# Cortex_M1 register map
Vendor: Arm Ltd.; Series: ARMv6-M; File version: 1.0.0
Cortex-M1 core peripherals (ARMv6-M): System Control Space and CoreSight debug components. Generated from CMSIS-Core 6.3.0 (CMSIS-Core 6.1) core_cm1.h with descriptions from the ARMv6-M Architecture Reference Manual and the Cortex-M1 Technical Reference Manual.
CPU: CM1 r0p0, little endian, no MPU, no FPU, 2 interrupt priority bits
Registers are 32-bit, read-only, reset 0x0 unless marked. A register's access mark holds for its fields unless they carry their own. Offsets are from the block's base; lines under a group give offsets from that group; [hi:lo] are bit positions; {n}, {i} and the like mark numbered series; 'fields as' and 'values as' point back to an identical list; <NAME> marks a mode.

## Memory map
0xE0001000 DWT blocks up to offset 0x1000 — Data Watchpoint and Trace unit: cycle counter and profiling counters, PC sampling, exception trace, and address/data comparators that raise watchpoints (halt or DebugMonitor), trigger the ETM/CTI or emit data trace. Needs DEMCR.TRCENA = 1.
0xE0002000 BPU blocks up to offset 0x1000 — Breakpoint Unit (Flash Patch and Breakpoint unit FPBv2 on STAR-MC1): up to eight hardware instruction breakpoint comparators.
0xE000E000 SCnSCB blocks up to offset 0xC — System control registers not in the SCB: the interrupt controller type and the implementation-defined Auxiliary Control Register.
0xE000E010 SysTick size 0x10 — 24-bit system timer that counts down from LOAD to 0 on the processor or reference clock and can raise the SysTick exception; the usual RTOS tick source. Banked per security state on ARMv8-M with the Security Extension.
0xE000E100 NVIC blocks up to offset 0x320 — Nested Vectored Interrupt Controller: enable, pending, active and priority registers for the external interrupts (IRQ0 = exception 16) and the software trigger register. Bit k of register n refers to IRQ 32n+k.
0xE000ED00 SCB size 0x28 — System Control Block: CPUID, exception control and state (ICSR, AIRCR, SHCSR), system configuration (SCR, CCR), system handler priorities, the fault status and address registers (CFSR, HFSR, DFSR, MMFAR, BFAR), CPU feature IDs, coprocessor access control, and on cores with caches the cache ID and maintenance registers.
0xE000EDF0 DCB size 0x10 — Debug Control Block: halting debug control and status (DHCSR), core register access from the debugger (DCRSR/DCRDR), vector catch, the DebugMonitor exception and trace enable (DEMCR), and on ARMv8-M debug authentication and security control.

## SCnSCB — System control registers not in the SCB: the interrupt controller type and the implementation-defined Auxiliary Control Register.
Base 0xE000E000
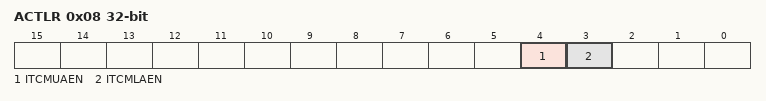
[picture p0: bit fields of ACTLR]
0x08 ACTLR rw — Auxiliary Control Register: implementation-defined controls that disable individual performance features (write buffering, instruction folding, interruptible multi-cycle instructions, FPU behaviours). Usually left at reset; DISDEFWBUF is useful to make imprecise BusFaults precise while debugging.
  [4] ITCMUAEN — Cortex-M1: enable the upper alias of the ITCM at 0x10000000.
  [3] ITCMLAEN — Cortex-M1: enable the lower alias of the ITCM at 0x00000000 (the ITCM otherwise appears only at its upper alias).

## SysTick — 24-bit system timer that counts down from LOAD to 0 on the processor or reference clock and can raise the SysTick exception; the usual RTOS tick source. Banked per security state on ARMv8-M with the Security Extension.
Base 0xE000E010
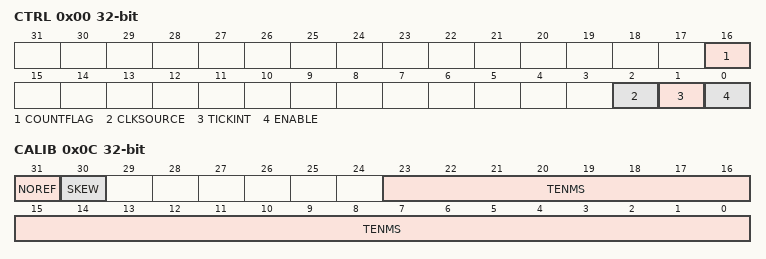
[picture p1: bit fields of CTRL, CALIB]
0x00 CTRL rw — SysTick Control and Status Register: enable, interrupt enable, clock source and the sticky count-to-zero flag.
  [16] COUNTFLAG ro — Reads 1 if the counter reached 0 since the last read of this register. Cleared by reading CTRL or writing VAL.
  [2] CLKSOURCE — Clock source: 0 = external reference clock (implementation defined, e.g. HCLK/8), 1 = processor clock.
    0=External reference clock (implementation defined); 1=Processor clock
  [1] TICKINT — 1 = counting down to 0 sets the SysTick exception pending; 0 = poll COUNTFLAG instead.
  [0] ENABLE — Counter enable: 1 = SysTick counts down from LOAD to 0 and reloads.
0x04 LOAD rw — SysTick Reload Value Register: value loaded into VAL when the counter reaches 0. A period of N clocks needs RELOAD = N-1.
  [23:0] RELOAD — Value loaded into VAL when the counter reaches 0. A period of N clocks needs RELOAD = N-1; 0 is legal but the counter then never fires.
0x08 VAL rw — SysTick Current Value Register: the current count. Any write clears it to 0 and clears CTRL.COUNTFLAG; the next reload comes from LOAD.
  [23:0] CURRENT — Current counter value. Any write clears the field to 0 and clears CTRL.COUNTFLAG.
0x0C CALIB — SysTick Calibration Register: implementation-defined reload value for a 10 ms tick and whether a reference clock exists.
  [31] NOREF — 1 = no separate reference clock: CLKSOURCE reads 1 and cannot be cleared.
  [30] SKEW — 1 = TENMS is not exact (a 10 ms tick cannot be produced exactly).
  [23:0] TENMS — Reload value for a 10 ms period with the reference clock, or 0 if unknown. Implementation defined.

## Licence text in the file
Copyright 2026 Arm Limited. Licensed under the Apache License, Version 2.0 (the "License"); you may not use this file except in compliance with the License. You may obtain a copy of the License at https://www.apache.org/licenses/LICENSE-2.0. Unless required by applicable law or agreed to in writing, software distributed under the License is distributed on an "AS IS" BASIS, WITHOUT WARRANTIES OR CONDITIONS OF ANY KIND, either express or implied. See the License for the specific language governing permissions and limitations under the License.
